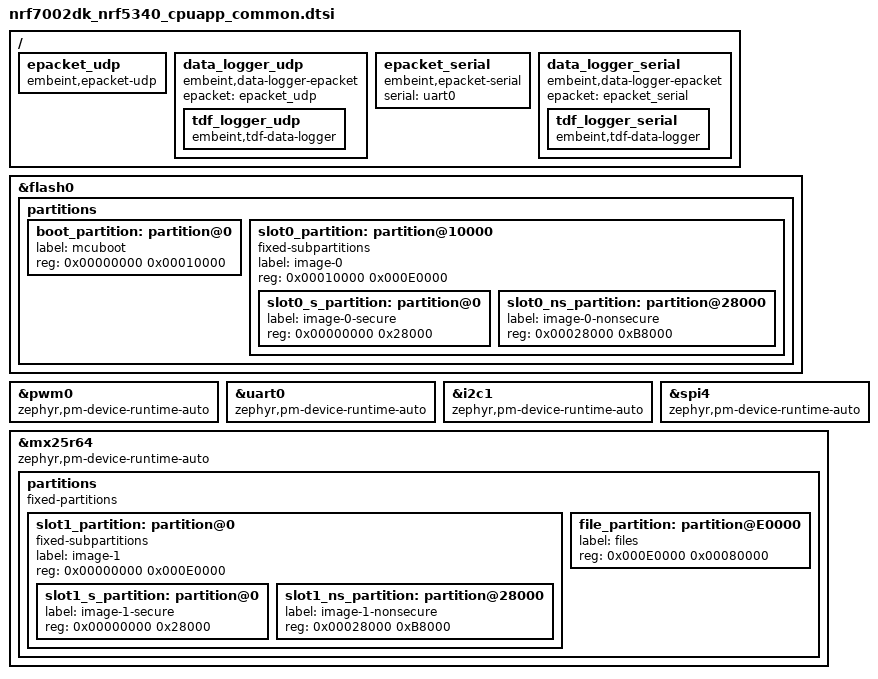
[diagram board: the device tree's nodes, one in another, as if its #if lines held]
/*
 * Copyright (c) 2025 Embeint Holdings Pty Ltd
 * SPDX-License-Identifier: FSL-1.1-ALv2
 */

#include <common/infuse_bluetooth.dtsi>

/* MCUboot secondary on external flash */
/delete-node/ &slot0_partition;
/delete-node/ &slot1_partition;

/ {
	epacket_udp: epacket_udp {
		compatible = "embeint,epacket-udp";
	};

	data_logger_udp: data_logger_udp {
		compatible = "embeint,data-logger-epacket", "embeint,data-logger";
		epacket = <&epacket_udp>;

		tdf_logger_udp: tdf_logger_udp {
			compatible = "embeint,tdf-data-logger";
		};
	};

	epacket_serial: epacket_serial {
		compatible = "embeint,epacket-serial";
		serial = <&uart0>;
	};

	data_logger_serial: data_logger_serial {
		compatible = "embeint,data-logger-epacket", "embeint,data-logger";
		epacket = <&epacket_serial>;

		tdf_logger_serial: tdf_logger_serial {
			compatible = "embeint,tdf-data-logger";
		};
	};

	data_logger_flash: data_logger_flash {
		compatible = "embeint,data-logger-flash-map", "embeint,data-logger";
		partition = <&data_logger_partition>;

		tdf_logger_flash: tdf_logger_flash {
			compatible = "embeint,tdf-data-logger";
		};
	};
};

&flash0 {
	partitions {
		boot_partition: partition@0 {
			label = "mcuboot";
			reg = <0x00000000 0x00010000>;
		};
		slot0_partition: partition@10000 {
			compatible = "fixed-subpartitions";
			label = "image-0";
			reg = <0x00010000 0x000E0000>;
			ranges = <0x0 0x10000 0xE0000>;
			#address-cells = <1>;
			#size-cells = <1>;

			slot0_s_partition: partition@0 {
				label = "image-0-secure";
				reg = <0x00000000 0x28000>;
			};

			slot0_ns_partition: partition@28000 {
				label = "image-0-nonsecure";
				reg = <0x00028000 0xB8000>;
			};
		};
	};
};

&pwm0 {
	zephyr,pm-device-runtime-auto;
};
&uart0 {
	zephyr,pm-device-runtime-auto;
};
&i2c1 {
	zephyr,pm-device-runtime-auto;
};
&spi4 {
	zephyr,pm-device-runtime-auto;
};
&mx25r64 {
	zephyr,pm-device-runtime-auto;

	partitions {
		compatible = "fixed-partitions";
		#address-cells = <1>;
		#size-cells = <1>;

		slot1_partition: partition@0 {
			compatible = "fixed-subpartitions";
			label = "image-1";
			reg = <0x00000000 0x000E0000>;
			ranges = <0x0 0x0 0xE0000>;
			#address-cells = <1>;
			#size-cells = <1>;

			slot1_s_partition: partition@0 {
				label = "image-1-secure";
				reg = <0x00000000 0x28000>;
			};

			slot1_ns_partition: partition@28000 {
				label = "image-1-nonsecure";
				reg = <0x00028000 0xB8000>;
			};
		};
		file_partition: partition@E0000 {
			label = "files";
			reg = <0x000E0000 0x00080000>;
		};
		data_logger_partition: partition@160000 {
			label = "data_logger";
			reg = <0x00160000 0x006A0000>;
		};
	};
};

#ifdef INFUSE_IS_BOOTLOADER

/* Bootloader doesn't know about external flash */
/delete-node/ &data_logger_flash;
/delete-node/ &data_logger_partition;

#endif /* INFUSE_IS_BOOTLOADER */
